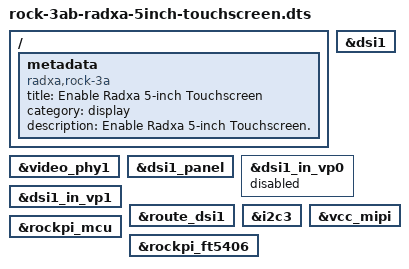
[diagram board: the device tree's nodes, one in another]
/dts-v1/;
/plugin/;

/ {
	metadata {
		title = "Enable Radxa 5-inch Touchscreen";
		compatible = "radxa,rock-3a", "radxa,rock-3b";
		category = "display";
		description = "Enable Radxa 5-inch Touchscreen.";
	};

	fragment@0 {
		target = <&video_phy1>;

		__overlay__ {
			status = "okay";
		};
	};

	fragment@1 {
		target = <&dsi1>;

		__overlay__ {
			status = "okay";
		};
	};

	fragment@2 {
		target = <&dsi1_panel>;

		__overlay__ {
			status = "okay";
		};
	};

	fragment@3 {
		target = <&dsi1_in_vp0>;

		__overlay__ {
			status = "disabled";
		};
	};

	fragment@4 {
		target = <&dsi1_in_vp1>;

		__overlay__ {
			status = "okay";
		};
	};

	fragment@5 {
		target = <&route_dsi1>;

		__overlay__ {
			status = "okay";
		};
	};

	fragment@6 {
		target = <&i2c3>;

		__overlay__ {
			status = "okay";
		};
	};

	fragment@7 {
		target = <&rockpi_mcu>;

		__overlay__ {
			status = "okay";
		};
	};

	fragment@8 {
		target = <&rockpi_ft5406>;

		__overlay__ {
			status = "okay";
		};
	};

	fragment@9 {
		target = <&vcc_mipi>;

		__overlay__ {
			status = "okay";
		};
	};

};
